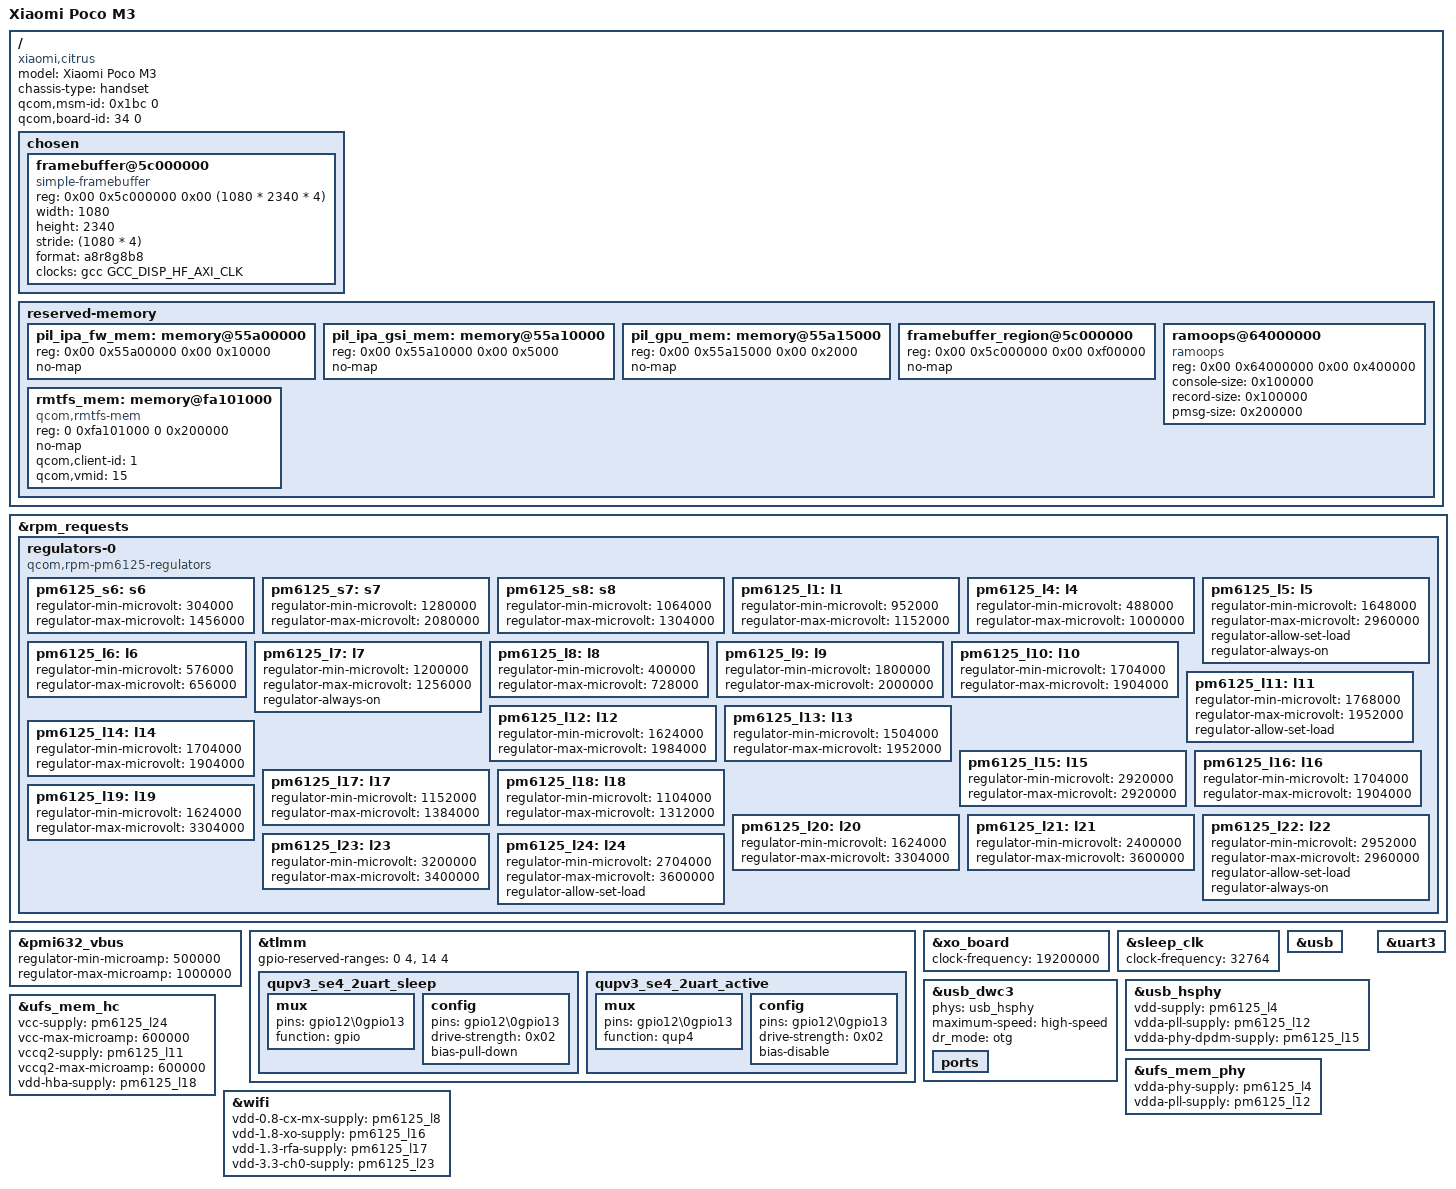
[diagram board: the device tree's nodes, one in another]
/dts-v1/;

#include "sm6115.dtsi"
#include "pmi632.dtsi"
#include "pm6125.dtsi"

/delete-node/ &pil_ipa_fw_mem;
/delete-node/ &pil_ipa_gsi_mem;
/delete-node/ &pil_gpu_mem;
/delete-node/ &rmtfs_mem;

/ {
 	model = "Xiaomi Poco M3";
 	compatible = "xiaomi,citrus", "qcom,sm6115";
	chassis-type = "handset";

	qcom,msm-id = <0x1bc 0>;
	qcom,board-id = <34 0>;

    chosen {
        #address-cells = <2>;
        #size-cells = <2>;
        ranges;
        framebuffer@5c000000 {
            compatible = "simple-framebuffer";
            reg = <0x00 0x5c000000 0x00 (1080 * 2340 * 4)>;
            width = <1080>;
            height = <2340>;
            stride = <(1080 * 4)>;
            format = "a8r8g8b8";
            clocks = <&gcc GCC_DISP_HF_AXI_CLK>;
        };
    };

    reserved-memory {
        #address-cells = <2>;
        #size-cells = <2>;
        ranges;

        pil_ipa_fw_mem: memory@55a00000 {
            reg = <0x00 0x55a00000 0x00 0x10000>;
            no-map;
        };

        pil_ipa_gsi_mem: memory@55a10000 {
            reg = <0x00 0x55a10000 0x00 0x5000>;
            no-map;
        };

        pil_gpu_mem: memory@55a15000 {
            reg = <0x00 0x55a15000 0x00 0x2000>;
            no-map;
        };

        framebuffer_region@5c000000 {
			reg = <0x00 0x5c000000 0x00 0xf00000>;
			no-map;
		};

        ramoops@64000000 {
			compatible = "ramoops";
			reg = <0x00 0x64000000 0x00 0x400000>;
			console-size = <0x100000>;
			record-size = <0x100000>;
			pmsg-size = <0x200000>;
		};

        rmtfs_mem: memory@fa101000 {
			compatible = "qcom,rmtfs-mem";
			reg = <0 0xfa101000 0 0x200000>;
			no-map;

			qcom,client-id = <1>;
			qcom,vmid = <15>;
		};
    };
};

&rpm_requests {
	regulators-0 {
		compatible = "qcom,rpm-pm6125-regulators";

		pm6125_s6: s6 {
			regulator-min-microvolt = <304000>; // true
			regulator-max-microvolt = <1456000>; // true
		};

		pm6125_s7: s7 {
			regulator-min-microvolt = <1280000>; // true
			regulator-max-microvolt = <2080000>; // fixed
		};

		pm6125_s8: s8 {
			regulator-min-microvolt = <1064000>; // true
			regulator-max-microvolt = <1304000>; // true
		};

		pm6125_l1: l1 {
			regulator-min-microvolt = <952000>; // true
			regulator-max-microvolt = <1152000>; // true
		};

		pm6125_l4: l4 {
			regulator-min-microvolt = <488000>; // true
			regulator-max-microvolt = <1000000>; // true
		};

		pm6125_l5: l5 {
			regulator-min-microvolt = <1648000>; // true
			regulator-max-microvolt = <2960000>; // true
			regulator-allow-set-load;
			regulator-always-on;
		};

		pm6125_l6: l6 {
			regulator-min-microvolt = <576000>; // true
			regulator-max-microvolt = <656000>; // true
		};

		pm6125_l7: l7 {
			regulator-min-microvolt = <1200000>; // true
			regulator-max-microvolt = <1256000>; // true
			regulator-always-on;
		};

		pm6125_l8: l8 {
			regulator-min-microvolt = <400000>; // true
			regulator-max-microvolt = <728000>; // true
		};

		pm6125_l9: l9 {
			regulator-min-microvolt = <1800000>; // true
			regulator-max-microvolt = <2000000>; // true
		};

		pm6125_l10: l10 {
			regulator-min-microvolt = <1704000>; // true
			regulator-max-microvolt = <1904000>; // true
		};

		pm6125_l11: l11 {
			regulator-min-microvolt = <1768000>; // fixed 
			regulator-max-microvolt = <1952000>; // true
			regulator-allow-set-load;
		};

		pm6125_l12: l12 {
			regulator-min-microvolt = <1624000>; // true
			regulator-max-microvolt = <1984000>; // true
		};

		pm6125_l13: l13 {
			regulator-min-microvolt = <1504000>; // true
			regulator-max-microvolt = <1952000>; // true
		};

		pm6125_l14: l14 {
			regulator-min-microvolt = <1704000>; // true
			regulator-max-microvolt = <1904000>; // true
		};

		pm6125_l15: l15 {
			regulator-min-microvolt = <2920000>; // true
			regulator-max-microvolt = <2920000>; // fixed
		};

		pm6125_l16: l16 {
			regulator-min-microvolt = <1704000>; // true
			regulator-max-microvolt = <1904000>; // true
		};

		pm6125_l17: l17 {
			regulator-min-microvolt = <1152000>; // true
			regulator-max-microvolt = <1384000>; // true
		};

		pm6125_l18: l18 {
			regulator-min-microvolt = <1104000>; // true
			regulator-max-microvolt = <1312000>; // true
		};

		pm6125_l19: l19 {
			regulator-min-microvolt = <1624000>; // true
			regulator-max-microvolt = <3304000>; // true
		};

		pm6125_l20: l20 {
			regulator-min-microvolt = <1624000>; // true
			regulator-max-microvolt = <3304000>; // true
		};

		pm6125_l21: l21 {
			regulator-min-microvolt = <2400000>; // true
			regulator-max-microvolt = <3600000>; // true
		};

		pm6125_l22: l22 {
			regulator-min-microvolt = <2952000>; // true
			regulator-max-microvolt = <2960000>; // true
			regulator-allow-set-load;
			regulator-always-on;
		};

		pm6125_l23: l23 {
			regulator-min-microvolt = <3200000>; // true
			regulator-max-microvolt = <3400000>; // true
		};

		pm6125_l24: l24 { 
			regulator-min-microvolt = <2704000>; // true
			regulator-max-microvolt = <3600000>; // true
			regulator-allow-set-load;
		};
	};
};

&pmi632_vbus {
	regulator-min-microamp = <500000>;
	regulator-max-microamp = <1000000>;
	status = "okay";
};

&tlmm {
    gpio-reserved-ranges = <0 4>, <14 4>;

	qupv3_se4_2uart_sleep {
		phandle = <0x144>;

		mux {
			pins = "gpio12\0gpio13";
			function = "gpio";
		};

		config {
			pins = "gpio12\0gpio13";
			drive-strength = <0x02>;
			bias-pull-down;
		};
	};
	qupv3_se4_2uart_active {
		phandle = <0x143>;

		mux {
			pins = "gpio12\0gpio13";
			function = "qup4";
		};

		config {
			pins = "gpio12\0gpio13";
			drive-strength = <0x02>;
			bias-disable;
		};
	};
};

&xo_board {
	clock-frequency = <19200000>;
};

&sleep_clk {
	clock-frequency = <32764>;
};

&usb {
	status = "okay";
};

/delete-node/ &usb_qmpphy;
&usb_dwc3 {
phys = <&usb_hsphy>;
phy-names = "usb2-phy";
	ports {
	/delete-node/ port@1;
	};

};

&usb_dwc3 {
	maximum-speed = "high-speed";
	dr_mode = "otg";

	phys = <&usb_hsphy>;
	phy-names = "usb2-phy";
};

&usb_hsphy {
	vdd-supply = <&pm6125_l4>;
	vdda-pll-supply = <&pm6125_l12>;
	vdda-phy-dpdm-supply = <&pm6125_l15>;
	status = "okay";
};

&ufs_mem_hc {
	vcc-supply = <&pm6125_l24>;
	vcc-max-microamp = <600000>;
	vccq2-supply = <&pm6125_l11>;
	vccq2-max-microamp = <600000>;
	vdd-hba-supply = <&pm6125_l18>;
	status = "okay";
};

&ufs_mem_phy {
	vdda-phy-supply = <&pm6125_l4>;
	vdda-pll-supply = <&pm6125_l12>;
	status = "okay";
};

&wifi {
	vdd-0.8-cx-mx-supply = <&pm6125_l8>;
	vdd-1.8-xo-supply = <&pm6125_l16>;
	vdd-1.3-rfa-supply = <&pm6125_l17>;
	vdd-3.3-ch0-supply = <&pm6125_l23>;
	status = "okay";
};

&uart3 {
	status = "okay";
};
